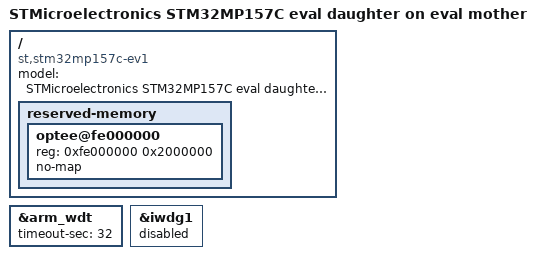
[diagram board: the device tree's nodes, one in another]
// SPDX-License-Identifier: (GPL-2.0+ OR BSD-3-Clause)
/*
 * Copyright (C) STMicroelectronics 2022 - All Rights Reserved
 * Author: Alexandre Torgue <alexandre.torgue@foss.st.com> for STMicroelectronics.
 */

/dts-v1/;

#include "stm32mp157c-ev1-no-scmi.dts"
#include "stm32mp157-scmi.dtsi"
#include "stm32mp15xc-scmi.dtsi"

/ {
	model = "STMicroelectronics STM32MP157C eval daughter on eval mother";
	compatible = "st,stm32mp157c-ev1", "st,stm32mp157c-ed1", "st,stm32mp157";

	reserved-memory {
		optee@fe000000 {
			reg = <0xfe000000 0x2000000>;
			no-map;
		};
	};
};

&arm_wdt {
	timeout-sec = <32>;
	bootph-all;
	status = "okay";
};

&iwdg1 {
	/* IWDG1 is secure and managed through arm_wdt */
	status = "disabled";
};
